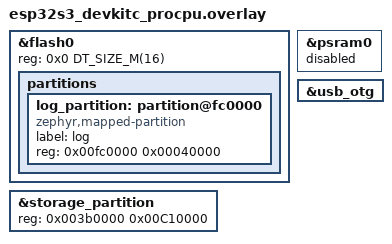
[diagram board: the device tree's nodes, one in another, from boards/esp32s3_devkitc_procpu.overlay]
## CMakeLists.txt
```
# SPDX-License-Identifier: Apache-2.0
#
# joy_bridge — Zephyr port of ESP32-BLE5-NSController-Emulator
# (Nintendo Switch Pro2 controller emulation over BLE).
#
# Migrated from the upstream ESP-IDF project. The layering is preserved:
#   - portable core: app/ (utils, state) / controller(HID) / codec(ns2)
#   - platform glue (Zephyr): ble/ (bt host), storage/ (settings)
#   - host input: usb_host/ (XInput class + host glue) + input/ (XInput->Pro2);
#                 the native UHC driver is the modules/uhc_dwc2_esp32 module

cmake_minimum_required(VERSION 3.20.0)

# Reusable in-tree Zephyr modules (must be on ZEPHYR_EXTRA_MODULES before
# find_package(Zephyr) so their Kconfig + sources are picked up):
#   - journal:        persistent flash-backed offline event log (CONFIG_JOURNAL)
#   - uhc_dwc2_esp32: native ESP32-S3 DWC2 USB host controller (CONFIG_UHC_DWC2)
list(APPEND ZEPHYR_EXTRA_MODULES
  ${CMAKE_CURRENT_SOURCE_DIR}/modules/journal
  ${CMAKE_CURRENT_SOURCE_DIR}/modules/uhc_dwc2_esp32
)

find_package(Zephyr REQUIRED HINTS $ENV{ZEPHYR_BASE})
project(joy_bridge C)

# Public headers (mirrors the upstream main/include tree).
target_include_directories(app PRIVATE include)

# Always-built portable core + platform glue. CONFIGURE_DEPENDS re-globs when
# files are added/removed so the build doesn't need a manual reconfigure.
file(GLOB_RECURSE app_sources CONFIGURE_DEPENDS
  src/main.c
  src/app/*.c
  src/controller/*.c
  src/codec/*.c
  src/ble/*.c
  src/storage/*.c
  src/input/*.c
  src/usb_host/*.c
)

target_sources(app PRIVATE ${app_sources})

# ---- USB host (input devices) -----------------------------------------------
# The native UHC host-controller driver now lives in the reusable module
# modules/uhc_dwc2_esp32 (added to ZEPHYR_EXTRA_MODULES above). The in-app class
# drivers (xinput_class.c / kbd_class.c) still use the experimental USB host
# stack's private class API (usbh_device.h / usbh_class.h) — no public header
# yet, same as the in-tree UVC host class — so they need that private include dir.
if(CONFIG_JOY_BRIDGE_USB_XINPUT OR CONFIG_JOY_BRIDGE_USB_KBD)
  target_include_directories(app PRIVATE ${ZEPHYR_BASE}/subsys/usb/host)
endif()
```

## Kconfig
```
# SPDX-License-Identifier: Apache-2.0
#
# Application Kconfig for joy_bridge. Mirrors the upstream main/Kconfig.projbuild
# options (symbol names kept identical to minimise churn in the ported sources)
# and adds Zephyr-specific knobs.

mainmenu "Joy Bridge (NS2 Controller Emulator)"

menu "NSController Configuration"

config MCU_DEBUG
	bool "Enable MCU debug logging"
	default n
	help
	  Enable detailed debug output for MCU operations (mirrors upstream
	  CONFIG_MCU_DEBUG). Prefer using the JOY_BRIDGE log level for runtime
	  filtering; this gates a handful of extra-verbose code paths.

config SAVE_PAIRING_INFO
	bool "Save pairing information"
	default y
	help
	  Persist pairing information (LTK / peer address) to non-volatile
	  storage for automatic reconnection on next boot.

config HID_REPORT_INTERVAL
	int "HID Report Interval (ms)"
	default 15
	range 5 100
	help
	  Interval between HID input report notifications. Lower values reduce
	  latency at the cost of CPU and BLE bandwidth. This is now only the
	  FALLBACK the report pacer uses when no link is up; with a connection
	  the send grid tracks the negotiated interval (clamped to 5-30 ms).

config JOY_BRIDGE_REPORT_BURST
	int "HID report fresh-input burst budget"
	default 3
	range 1 8
	help
	  How many fresh committed input reports may send back-to-back without
	  waiting for the send grid, per report_pacer.c. Sparse change-driven
	  input (e.g. keyboard) goes out immediately; dense streams degrade to
	  the interval cap once the burst is spent, protecting the BLE TX pool.

config JOY_BRIDGE_BLE_MIN_CONN_INTERVAL
	int "Requested minimum connection interval (units of 1.25 ms)"
	default 4
	help
	  Lower bound (in 1.25 ms units) the peripheral will accept when the NS2
	  console requests a connection-parameter update. 4 = 5 ms (sub-spec).
	  NOTE: the Zephyr host honours this only with BT_CONN_PARAM_ANY=y, and
	  the ESP32-S3 controller blob currently CANNOT enforce sub-7.5 ms — see
	  the 5 ms feasibility notes in src/ble/ble.c.

config JOY_BRIDGE_BLE_FAST_CONN_INTERVAL
	int "Post-pairing fast connection interval (units of 1.25 ms; 0 = off)"
	default 0
	help
	  After security level 4, request this connection interval from the NS2 to
	  cut input latency. Units of 1.25 ms; 4 = 5 ms / 200 Hz (prj.conf sets 4).
	  Verified on hardware: NS2 connects at 5 ms but power-saves to ~30 ms a few
	  seconds later; on_le_param_updated() re-requests this value whenever the
	  interval regresses above it, and NS2 then holds 5 ms. Requested only after
	  pairing so it cannot perturb the handshake; the negotiated result is logged
	  by on_le_param_updated(). 0 = never poke the link.

config JOY_BRIDGE_SLEEP_ON_NS2_OFF
	bool "Deep-sleep the ESP32 when the BLE link to the NS2 drops"
	select POWEROFF
	default n
	help
	  When the BLE link to the NS2 drops (the console sleeps / powers off, or
	  the link is otherwise lost), enter deep sleep instead of re-advertising.
	  Re-advertising the wake packet would immediately wake the console back up,
	  so this is the only way to actually power down with it (~10 uA). Wake by
	  pressing BOOT (GPIO0): the chip reboots, re-advertises, and the NS2
	  reconnects. Tap BOOT briefly — holding it through the wake-reset enters
	  serial-download mode, since GPIO0 is the boot strapping pin.

config JOY_BRIDGE_DIAG_HEXDUMP
	bool "DIAG: hexdump NS2 <-> controller ATT traffic"
	default n
	help
	  Capture the BLE application-layer protocol for reverse-engineering: log
	  every NS2<->controller ATT exchange as an INFO-level hexdump tagged
	  "[DIAG] ..." — command writes on 0x0016 (incl. the cmd-0x15 key
	  agreement), command responses on 0x001e, other inbound writes, the
	  constant reads, and CCC subscribe changes. grep a serial capture for
	  "[DIAG]" to lift out the raw bytes. Requires the JOY_BRIDGE log level to
	  be INF or higher. Leave OFF for normal use.

config JOY_BRIDGE_DIAG_HEXDUMP_HID
	bool "DIAG: also hexdump HID input reports (high rate)"
	depends on JOY_BRIDGE_DIAG_HEXDUMP
	default n
	help
	  Additionally hexdump every outbound HID input-report notification on
	  0x000e. These fire every HID_REPORT_INTERVAL ms (5-15), so this is very
	  verbose and can overrun the log backend; enable only for short captures.

config JOY_BRIDGE_DIAG_LATENCY
	bool "DIAG: measure input->notify latency and USB report rate"
	default n
	select UHC_DWC2_DIAG_LATENCY if UHC_DWC2
	help
	  Log, once per second, the rate of XInput reports consumed and the
	  average/max latency from an XInput report arriving to the resulting
	  HID notify being queued (in microseconds). For latency tuning; leave
	  OFF for normal use.

module = JOY_BRIDGE
module-str = joy_bridge
source "subsys/logging/Kconfig.template.log_config"

endmenu

source "Kconfig.zephyr"

# joy_bridge USB host (XInput) symbols. Sourced last so it can depend on the
# Zephyr UHC_DRIVER / USB_HOST_STACK symbols pulled in by Kconfig.zephyr.
# rsource: resolve relative to this file's dir (the app), not $srctree.
rsource "Kconfig.dwc2"
```

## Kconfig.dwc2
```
# SPDX-License-Identifier: Apache-2.0
#
# joy_bridge USB host input options.
#
# Sourced AFTER Kconfig.zephyr (see Kconfig) so the upstream USB_HOST_STACK
# symbol already exists and can be depended on here. The native DWC2 host-
# controller driver's Kconfig (CONFIG_UHC_DWC2) now lives in the reusable
# modules/uhc_dwc2_esp32 module.

config JOY_BRIDGE_USB_XINPUT
	bool "XInput USB host gamepad as the controller input source"
	depends on USB_HOST_STACK
	help
	  Read a wired XInput (Xbox-style) controller plugged into the ESP32-S3
	  USB-OTG port and map its gamepad reports onto the emulated Pro2 HID
	  report. Requires a working host controller (CONFIG_UHC_DWC2, provided by
	  the modules/uhc_dwc2_esp32 module).

config JOY_BRIDGE_USB_KBD
	bool "USB HID boot-protocol keyboard as a controller input source"
	depends on USB_HOST_STACK
	default n
	help
	  Read a wired USB HID boot-protocol keyboard (interface class 0x03,
	  subclass 0x01 boot, protocol 0x01 keyboard) plugged into the
	  ESP32-S3 USB-OTG port and merge its key presses with the XInput
	  input onto the emulated Pro2 HID report. Boot-protocol keyboards
	  only — NKRO/report-protocol-only keyboards are unsupported.
```

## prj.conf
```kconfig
# SPDX-License-Identifier: Apache-2.0
#
# joy_bridge application config. Target board: esp32s3_devkitc.

# ---- C library / heap -------------------------------------------------------
# The ported codec/controller use malloc()/free(); give libc a real arena.
CONFIG_COMMON_LIBC_MALLOC_ARENA_SIZE=32768
CONFIG_CPP=n

# ESP32-S3 external PSRAM: disabled for initial bring-up. The octal-mode config
# carried over from the Hello World overlay hangs early SoC init on boards
# without octal PSRAM. Not required by the app. Re-enable with the correct mode
# (quad vs octal) once the board PSRAM variant is confirmed.
# CONFIG_ESP_SPIRAM=y
# CONFIG_SPIRAM_MODE_OCT=y

# ---- Logging ----------------------------------------------------------------
CONFIG_LOG=y
CONFIG_JOY_BRIDGE_LOG_LEVEL_INF=y

# ---- Bluetooth host ---------------------------------------------------------
CONFIG_BT=y
CONFIG_BT_PERIPHERAL=y
CONFIG_BT_CENTRAL=n
CONFIG_BT_DEVICE_NAME="Pro Controller 2"

# Extended advertising (upstream uses ble_gap_ext_adv_* / legacy-PDU ext adv).
CONFIG_BT_EXT_ADV=y

# GATT server with our static service definition.
CONFIG_BT_GATT_DYNAMIC_DB=n

# No GATT robust caching — upstream NimBLE has none. Robust caching adds the
# Database-Hash / Client-Supported-Features attributes and can answer a client's
# first request with ATT "Database Out Of Sync" (0x12); both diverge from the
# table NS2 expects. (Default is y on this Zephyr.)
CONFIG_BT_GATT_CACHING=n

# *** Match the genuine Pro2 ATT table: drop the default GAP/GATT services ***
# ROOT CAUSE of "controller never appears" (proven by symmetric [DIAG] capture):
# NS2 connects (itvl=12, same as upstream) and exchanges MTU, then — unlike with
# upstream — issues NO subscribe and NO command write. It discovers the GATT
# table, finds the mandatory Zephyr GAP(0x1800)+GATT(0x1801) services that a real
# Pro2 lacks (these also shift HID 0x000e->0x0018 and the cmd channel
# 0x0016->0x001f), and silently declines. Upstream omits both default services
# (gatt.c: // ble_svc_gap_init(); // ble_svc_gatt_init();), so its table is the
# exact Pro2 layout starting at 0x0001.
#   BT_GAP_SVC=n               removes the GAP 0x1800 service (config-only).
#   BT_GATT_GAP_SVC_VALIDATE=n drops the spec "exactly one GAP service" check;
#                              otherwise bt_enable() returns -EINVAL with 0 GAP svcs.
#   BT_GATT_SERVICE_CHANGED=n  shrinks the GATT 0x1801 service to a 1-handle stub.
# (Fully removing 0x1801 + re-adding the Pro2 vendor descriptors for an EXACT
#  handle match would need a small Zephyr-host patch; this config-only step is the
#  first experiment — the [DIAG] write/subscribe handles on the next NS2 attempt
#  show whether removing GAP is sufficient or exact handles are still required.)
CONFIG_BT_GAP_SVC=n
CONFIG_BT_GATT_GAP_SVC_VALIDATE=n
CONFIG_BT_GATT_SERVICE_CHANGED=n

# Security / bonding. Upstream injects a pre-derived LTK rather than running a
# standard pairing exchange; keep SMP + settings-backed bonding available.
CONFIG_BT_SMP=y
CONFIG_BT_BONDABLE=y

# Match upstream's NS2 security model (src/device.c: sm_io_cap=NO_IO, sm_mitm=0,
# sm_sc=0 -> Just-Works, legacy-capable, UNauthenticated). Zephyr defaults the
# opposite (BT_SMP_ENFORCE_MITM=y and BT_SMP_SC_PAIR_ONLY=y, both `default y`),
# so the peripheral demands authenticated Secure-Connections-only pairing and
# would reject the console's Just-Works/legacy handshake -> no encryption -> the
# controller never registers on the Change Grip/Order screen. Disabling
# SC_PAIR_ONLY also compiles the legacy periph_ltk path in src/ble/ble_store.c
# so the injected NS2 LTK is served on the console's rand=0/ediv=0 enc request.
CONFIG_BT_SMP_ENFORCE_MITM=n
CONFIG_BT_SMP_SC_PAIR_ONLY=n
CONFIG_BT_SETTINGS=y
CONFIG_SETTINGS=y
CONFIG_FLASH=y
CONFIG_FLASH_MAP=y
CONFIG_NVS=y

# Single connection (one NS2 console at a time).
CONFIG_BT_MAX_CONN=1
CONFIG_BT_MAX_PAIRED=1

# BT RX work-queue stack. Incoming ATT (the GATT write callback ->
# cmd_process() -> cmd_0x15_handler()) runs here (CONFIG_BT_RECV_WORKQ_BT=y).
# The cmd-0x15 subcmd 0x02 path calls aes128_ecb() -> bt_encrypt_be(), which on
# this build resolves to the PSA/mbedTLS software AES (CONFIG_BT_HOST_CRYPTO=y,
# not the HCI LE-Encrypt path). That, plus the surrounding GATT/cmd processing,
# is deep enough to overflow the default 1200-byte stack and corrupt memory
# (observed: illegal-instruction fault in the scheduler ~1 ms after the
# subcmd-0x02 response, during the LTK exchange). Give it room.
CONFIG_BT_RX_STACK_SIZE=4096

# ATT MTU = 512 to match the genuine Pro2 (and upstream). The captured success
# trace shows NS2 negotiates MTU=512 then immediately reads 0x0003; our build
# negotiated only 247 and NS2 went silent right at that point. The server's RX
# ATT MTU is MIN(BT_L2CAP_RX_MTU, BT_L2CAP_TX_MTU), and BT_L2CAP_RX_MTU =
# BT_BUF_ACL_RX_SIZE - 4, so the RX buffer must be >= 516 to advertise MTU 512.
CONFIG_BT_L2CAP_TX_MTU=512
CONFIG_BT_BUF_ACL_TX_SIZE=251
CONFIG_BT_BUF_ACL_RX_SIZE=516

# *** 5 ms (sub-spec) connection interval enabler (HOST side) ***
# Removes the host's interval_min>=6 (7.5 ms) validation so the peripheral can
# accept the NS2 console's sub-spec params via the le_param_req callback.
# The CONTROLLER side (ESP32-S3 blob) is a separate, currently-unsolved gate:
# see the feasibility notes at the top of src/ble/ble.c.
CONFIG_BT_CONN_PARAM_ANY=y

# Post-pairing/reconnect fast connection interval (units of 1.25 ms).
# 4 = 5 ms / 200 Hz, matching the interval NS2 uses natively in its fast mode.
# On wake/reconnect NS2 frequently settles on its ~30 ms power-save interval and
# nothing pulls it back down, so input lags. fast_interval_work_fn() requests
# this value once security reaches L4 (fresh-pair OR bonded reconnect), retrying
# a few times. The controller floor is 3.75 ms so a 5 ms grant is accepted.
CONFIG_JOY_BRIDGE_BLE_FAST_CONN_INTERVAL=4

# HID input-report cadence (ms) — left at the default 15 ms. NOTE: a 5 ms cadence
# (to match the fast link) was tried and REGRESSED input on hardware: the NS2
# power-saves the link to ~30 ms periodically, and sending every 5 ms then floods
# the small BLE TX buffer pool (the "12 != 10" ACL/tx-context margin), so HID
# notifies stall/-ENOMEM and reports stop reaching the console. A proper low-
# latency cadence must track the *negotiated* connection interval rather than use
# a fixed value — see the report loop in src/controller/hid_controller.c.

# Use a fixed public identity address (upstream sets a Nintendo-prefixed MAC).
CONFIG_BT_PRIVACY=n

# Deep-sleep the ESP32 when the BLE link to the NS2 drops, instead of
# re-advertising (which would wake the console back up). Wake = BOOT/GPIO0
# press -> reboot -> re-advertise. Selects CONFIG_POWEROFF (sys_poweroff()).
CONFIG_JOY_BRIDGE_SLEEP_ON_NS2_OFF=y

# ---- Console / logging UART -------------------------------------------------
# Serial console for boot logs and the [DIAG] BLE captures. Host input is not a
# UART byte stream — it comes from XInput over USB host (see below).
CONFIG_SERIAL=y
CONFIG_UART_INTERRUPT_DRIVEN=y

# ---- USB host (XInput controller input) ------------------------------------
# Bring the on-chip ESP32-S3 USB-OTG core up in HOST mode (Full-Speed) and run
# the experimental Zephyr USB host stack, so a wired XInput (Xbox) controller
# plugged into the USB-OTG port drives the emulated Pro2.
#
# Upstream Zephyr has NO DWC2 host (UHC) driver for the S3 OTG core, so
# CONFIG_UHC_DWC2 selects the in-app uhc_dwc2_esp32 driver (and makes
# hal_espressif compile its USB wrapper HAL). USB host + UHC are EXPERIMENTAL
# (CONFIG_EXPERIMENTAL is auto-selected by USB_HOST_STACK / UHC_DRIVER).
CONFIG_USB_HOST_STACK=y
CONFIG_UHC_DRIVER=y
CONFIG_UHC_DWC2=y
CONFIG_JOY_BRIDGE_USB_XINPUT=y
# USB HID boot-protocol keyboard as a second input source (merged with the pad:
# buttons OR, sticks last-writer-wins). Boot-protocol only — see AGENTS.md.
CONFIG_JOY_BRIDGE_USB_KBD=y

# ---- Persistent event journal (offline diagnostics) -------------------------
# Record curated low-rate events (boot+reset cause, BLE connect/disconnect+reason,
# security level, conn-interval changes, deep-sleep entry, USB bind) to a
# dedicated flash partition (log_partition, top 256 KB), replayed to the console
# on the next boot. Lets the device's behaviour while running on battery with no
# serial console be reviewed after the fact. Backed by FCB on its own partition —
# does NOT touch the NVS partition holding the NS2 bond. Provided by the reusable
# `journal` Zephyr module (modules/journal/); main.c calls journal_init() with
# log_partition's area id and ble_hid_ready as the flash-write gate.
CONFIG_JOURNAL=y
```

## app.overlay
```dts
/* 1. Expand total physical flash size to 16 MB */
&flash0 {
    reg = <0x0 DT_SIZE_M(16)>;
};

/* 2. Stretch the storage partition */
&storage_partition {
    reg = <0x003b0000 0x00C50000>;
};

/* 3. Enable the internal 8 MB PSRAM */
&psram0 {
    status = "okay";
    size = <DT_SIZE_M(8)>;
};

/* 4. Bring up USB-OTG in HOST mode for the XInput controller bridge.
 *
 * Reuse the existing "espressif,esp32-usb-otg" node (its binding includes
 * snps,dwc2.yaml, providing reg/interrupts/clocks). USB *device* (UDC) mode is
 * left disabled in prj.conf, so nothing else binds this compatible; the in-app
 * host driver binds it via DT_DRV_COMPAT espressif_esp32_usb_otg.
 */
&usb_otg {
    status = "okay";
};
```

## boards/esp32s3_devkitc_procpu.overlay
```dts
/*
 * Board-specific devicetree overlay for esp32s3_devkitc.
 *
 * Zephyr auto-applies boards/<board>.overlay when this board is the build
 * target (BOARD=esp32s3_devkitc/esp32s3/procpu), so this file needs no CMake
 * wiring. It holds the DevKitC-1 flash/PSRAM layout and the USB-OTG host-mode
 * bring-up for the XInput controller bridge.
 */

/* 1. Expand total physical flash size to 16 MB */
&flash0 {
    reg = <0x0 DT_SIZE_M(16)>;
};

/* 2. Stretch the storage partition.
 * Ends at 0xfc0000 (not 0x1000000): the top 256 KB is reserved for the
 * persistent-trace partition below. The start stays at 0x3b0000, and NVS fills
 * from the start, so the existing NS2 bond (in the low sectors) is unaffected by
 * trimming the unused tail. */
&storage_partition {
    reg = <0x003b0000 0x00C10000>;
};

/* 2a. Persistent event journal ring (CONFIG_JOURNAL).
 * Top 256 KB of flash, its own partition so the journal never shares the NVS
 * partition that holds the load-bearing bond. Bound by FCB in the reusable
 * `journal` module (modules/journal/), which main() points here by passing
 * PARTITION_ID(log_partition) to journal_init(). esptool-pullable:
 *   esptool read-flash 0xfc0000 0x40000 journal.bin (then `strings journal.bin`). */
&flash0 {
    partitions {
        log_partition: partition@fc0000 {
            /* Same compatible as every sibling in this AMP layout — the parent
             * `partitions` node is not a `fixed-partitions` node, so PARTITION_ID()
             * resolves via the mapped-partition path (as storage_partition does). */
            compatible = "zephyr,mapped-partition";
            label = "log";
            reg = <0x00fc0000 0x00040000>;
        };
    };
};

/* 3. PSRAM: left DISABLED, to match prj.conf (CONFIG_ESP_SPIRAM is off).
 * The octal-mode SPIRAM config carried over from the Hello-World overlay hung
 * early SoC init on this board, and the app does not need PSRAM. Keeping the node
 * disabled (rather than "okay" with an 8 MB size that nothing initialises) avoids
 * a half-enabled trap: re-enabling means flipping BOTH this status — with the
 * correct size — AND the Kconfig (CONFIG_ESP_SPIRAM + the right SPIRAM_MODE_xxx)
 * together. See AGENTS.md "Current state & known gaps". */
&psram0 {
    status = "disabled";
};

/* 4. Bring up USB-OTG in HOST mode for the XInput controller bridge.
 *
 * Reuse the existing "espressif,esp32-usb-otg" node (its binding includes
 * snps,dwc2.yaml, providing reg/interrupts/clocks). USB *device* (UDC) mode is
 * left disabled in prj.conf, so nothing else binds this compatible; the in-app
 * host driver binds it via DT_DRV_COMPAT espressif_esp32_usb_otg.
 */
&usb_otg {
    status = "okay";
};
```

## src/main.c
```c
/*
 * joy_bridge — application entry point.
 * Zephyr port of the upstream ESP-IDF app_main() init sequence.
 */

#include <zephyr/kernel.h>

#include "device.h"
#include "controller/hid_controller.h"
#include "storage.h"
#include "usb_host.h"
#include "ble/ble_iface.h"            /* ble_hid_ready() — journal flash-write gate */

#include <zephyr/storage/flash_map.h> /* PARTITION_ID(log_partition) */
#include <zephyr/logging/log.h>
LOG_MODULE_REGISTER(jb_app, CONFIG_JOY_BRIDGE_LOG_LEVEL);
#include "app_log.h"
#include <journal/journal.h>

int main(void) {
    /* First: replay any persisted offline journal to the console and mark this
     * boot (with the reset cause). Done before other init so the dump leads and
     * does not interleave with normal log output. Persists to log_partition;
     * ble_hid_ready gates flash writes to the settled-link window (never during
     * boot/pairing). No-op unless CONFIG_JOURNAL. */
    journal_init(PARTITION_ID(log_partition), ble_hid_ready);

    ESP_LOGI(LOG_APP, "Nintendo Switch Controller Emulator (joy_bridge)");
    ESP_LOGI(LOG_APP, "Starting initialization...");

    /* Persistent storage (settings) for controller config + pairing info. */
    if (storage_init() != 0) {
        ESP_LOGE(LOG_APP, "Storage init failed; continuing without persistence");
    }

    /* Controller type + firmware/pairing data from storage. */
    controller_type_init();
    if (controller_init() == 0) {
        ESP_LOGI(LOG_APP, "Controller firmware loaded (paired)");
    } else {
        ESP_LOGW(LOG_APP, "No pairing info; will pair on first connection");
    }

    /* HID report engine (double buffer + report thread, idle until subscribed). */
    if (g_hid_controller.ops->init(&g_hid_controller, g_controller_firmware.type) == 0) {
        ESP_LOGI(LOG_APP, "Controller initialized");
    } else {
        ESP_LOGE(LOG_APP, "Failed to initialize controller");
    }

    /* BLE stack: GATT service, identity, advertising. */
    if (ble_stack_init() != 0) {
        ESP_LOGE(LOG_APP, "BLE stack init failed");
    } else {
        ESP_LOGI(LOG_APP, "BLE stack initialized");
    }

#if defined(CONFIG_JOY_BRIDGE_USB_XINPUT) || defined(CONFIG_JOY_BRIDGE_USB_KBD)
    /* USB host (XInput pad / HID keyboard input). Started after BLE — the
     * load-bearing path comes up first, and a USB failure must never block it. */
    if (usb_host_start() == 0) {
        ESP_LOGI(LOG_APP, "USB host started");
    } else {
        ESP_LOGE(LOG_APP, "USB host start failed; continuing without host input");
    }
#endif

    /* Zephyr keeps the kernel + worker threads running after main returns. */
    return 0;
}
```

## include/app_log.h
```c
#ifndef _APP_LOG_H_
#define _APP_LOG_H_

/*
 * ESP-IDF -> Zephyr logging shim.
 *
 * The ported sources use ESP_LOGx(TAG, fmt, ...). Zephyr selects the log module
 * per translation unit, so the TAG argument is unused here (it is still defined
 * as a string literal elsewhere, e.g. LOG_APP/LOG_HID, and simply discarded by
 * these macros).
 *
 * LOG modules are grouped by subsystem (jb_app, jb_ble, jb_codec, jb_ctrl,
 * jb_storage, jb_usb). Before including this header, the subsystem's primary .c
 * registers the module and the other .c files in that subsystem declare it:
 *
 *     #include <zephyr/logging/log.h>
 *     LOG_MODULE_REGISTER(jb_<subsys>, CONFIG_JOY_BRIDGE_LOG_LEVEL);  // once per subsystem
 *     // ...or, in the subsystem's other files:
 *     LOG_MODULE_DECLARE(jb_<subsys>, CONFIG_JOY_BRIDGE_LOG_LEVEL);
 *     #include "app_log.h"
 */

#include <zephyr/logging/log.h>

#define ESP_LOGE(tag, ...) LOG_ERR(__VA_ARGS__)
#define ESP_LOGW(tag, ...) LOG_WRN(__VA_ARGS__)
#define ESP_LOGI(tag, ...) LOG_INF(__VA_ARGS__)
#define ESP_LOGD(tag, ...) LOG_DBG(__VA_ARGS__)

#endif /* _APP_LOG_H_ */
```

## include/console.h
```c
#ifndef _CONSOLE_H_
#define _CONSOLE_H_

#include <stdint.h>

#define NS2_BD_ADDR_LEN 6

/*
 * Portable BLE address holder. Decoupled from any host-stack address type so
 * the codec/controller layers do not pull in the Zephyr bluetooth headers.
 * The ble/ layer translates to/from bt_addr_le_t.
 *
 * val[] is stored little-endian (LSB first), matching the upstream NimBLE
 * ble_addr_t convention and Zephyr's bt_addr_le_t.
 */
typedef struct {
    uint8_t type;                   /* 0 = public */
    uint8_t val[NS2_BD_ADDR_LEN];
} ns2_addr_t;

typedef struct {
    ns2_addr_t ble_addr;
    uint16_t   conn_handle;         /* legacy field; see ble layer for live conn */
    uint16_t   mtu;
} console_ns2_t;

extern console_ns2_t g_console_ns2;

#endif /* _CONSOLE_H_ */
```

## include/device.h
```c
#ifndef _DEVICE_H_
#define _DEVICE_H_

/*
 * Central application header for the portable core. Aggregates the cross-layer
 * declarations the upstream sources expect from "device.h", but free of any
 * host-stack (NimBLE/Zephyr-bt) types — those live behind ble/ble_iface.h.
 */

#include <stdint.h>
#include <stdbool.h>

#include "console.h"
#include "controller/controller.h"
#include "ble/ble_iface.h"

/* Log "tags" — kept as string literals for call-site parity with the upstream
 * ESP_LOGx(TAG, ...) calls. The app_log.h shim discards the tag argument; the
 * active Zephyr log module is chosen per-file via LOG_MODULE_REGISTER(). */
#define LOG_APP        "app"
#define LOG_HID        "hid"
#define LOG_BLE_GATT   "ble_gatt"
#define LOG_BLE_GAP    "ble_gap"
#define LOG_BLE_NVS    "ble_nvs"

#endif /* _DEVICE_H_ */
```

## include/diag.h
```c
/*
 * DIAG — config-gated hexdump capture of the NS2 <-> controller ATT traffic.
 *
 * Enable with CONFIG_JOY_BRIDGE_DIAG_HEXDUMP=y (and, for the high-rate HID
 * input reports, CONFIG_JOY_BRIDGE_DIAG_HEXDUMP_HID=y). Every captured PDU is
 * emitted at INFO level tagged "[DIAG] ...", so a serial capture can be grepped
 * for "[DIAG]" and the raw bytes lifted out for offline analysis (e.g. feed to
 * Wireshark via text2pcap). Disabled builds compile these to nothing.
 *
 * Include AFTER LOG_MODULE_REGISTER()/app_log.h in the .c file so the LOG_*
 * macros bind to that translation unit's log module.
 *
 * The tag passed to LOG_DIAG_DUMP must be a string literal: it is concatenated
 * with "[DIAG] " at compile time, which also keeps the hexdump label pointer in
 * static storage (deferred logging stores the label by pointer, not by copy).
 */
#ifndef _DIAG_H_
#define _DIAG_H_

#include <zephyr/logging/log.h>

#if defined(CONFIG_JOY_BRIDGE_DIAG_HEXDUMP)
#define LOG_DIAG(...)              LOG_INF(__VA_ARGS__)
#define LOG_DIAG_DUMP(tag, d, l)   LOG_HEXDUMP_INF((d), (l), "[DIAG] " tag)
#else
#define LOG_DIAG(...)              ((void)0)
#define LOG_DIAG_DUMP(tag, d, l)   ((void)0)
#endif

#if defined(CONFIG_JOY_BRIDGE_DIAG_HEXDUMP_HID)
#define LOG_DIAG_DUMP_HID(tag, d, l)  LOG_HEXDUMP_INF((d), (l), "[DIAG] " tag)
#else
#define LOG_DIAG_DUMP_HID(tag, d, l)  ((void)0)
#endif

#endif /* _DIAG_H_ */
```

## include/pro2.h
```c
#ifndef _PRO2_H_
#define _PRO2_H_

/* Pro2-specific device init and pairing persistence. */

int pro2_device_init(void);
int pro2_pairing_info_save(void);
int pro2_pairing_info_erase(void);

#endif /* _PRO2_H_ */
```

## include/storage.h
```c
#ifndef _STORAGE_H_
#define _STORAGE_H_

/*
 * Tiny key/value persistence abstraction, replacing the upstream ESP-IDF NVS
 * usage. Backed by the Zephyr settings subsystem (see src/storage/storage.c).
 *
 * Keys are namespaced (namespace + key) the same way the original code grouped
 * values into NVS namespaces (CONFIG / PAIRING_PRO2 / ...).
 */

#include <stdint.h>
#include <stddef.h>

/* Namespaces (mirror upstream NVS namespace names). */
#define STORAGE_NS_CONFIG        "config"
#define STORAGE_NS_PAIRING_PRO2  "pair_pro2"
#define STORAGE_NS_PAIRING_JC    "pair_jc"

/* Keys (mirror upstream NVS keys). */
#define STORAGE_KEY_CONTROLLER_TYPE  "ctrl_type"
#define STORAGE_KEY_CTRL_ADDR        "ctrl_mac"
#define STORAGE_KEY_HOST_ADDR        "host_mac"
#define STORAGE_KEY_LTK              "ble_ltk"

#ifdef __cplusplus
extern "C" {
#endif

/* Initialise the storage backend. Returns 0 on success. */
int storage_init(void);

/* Read a blob. On entry *len is the buffer capacity; on success it holds the
 * bytes read. Returns 0 on success, -ENOENT if absent, other negative errno
 * on error. */
int storage_get_blob(const char *ns, const char *key, void *out, size_t *len);

/* Write a blob. Returns 0 on success. */
int storage_set_blob(const char *ns, const char *key, const void *in, size_t len);

/* Read / write a single byte. */
int storage_get_u8(const char *ns, const char *key, uint8_t *out);
int storage_set_u8(const char *ns, const char *key, uint8_t val);

/* Erase every key under a namespace. Returns 0 on success. */
int storage_erase_namespace(const char *ns);

#ifdef __cplusplus
}
#endif

#endif /* _STORAGE_H_ */
```

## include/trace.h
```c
#ifndef _TRACE_H_
#define _TRACE_H_

/*
 * Persistent event trace — a curated, low-rate log of significant runtime
 * events written to a dedicated flash partition (log_partition) so the device's
 * behaviour while running *offline* (on battery, no serial console attached) can
 * be reviewed later.
 *
 * On boot the previously stored trace is dumped to the console; new events are
 * appended durably (each append commits to flash, so an abrupt power loss — e.g.
 * a flat battery — loses at most the line in flight). Backed by Zephyr's Flash
 * Circular Buffer over its OWN partition; it never touches the settings/NVS
 * partition that holds the load-bearing NS2 bond. See src/app/trace.c.
 *
 * Gated by CONFIG_JOY_BRIDGE_PERSIST_LOG; compiles to nothing when disabled.
 */

#include <zephyr/toolchain.h>

#ifdef __cplusplus
extern "C" {
#endif

#ifdef CONFIG_JOY_BRIDGE_PERSIST_LOG

/* Mount the flash ring, replay any stored events to the console, and append a
 * boot marker (with the reset cause). Call once, early in main(). */
void jb_trace_init(void);

/* Record one curated event. The line is enqueued to a small RAM ring and
 * written to flash later by a low-priority worker (only once the BLE link is
 * settled) — NEVER inline, because writing the on-chip flash stalls the XIP
 * cache and disrupts the BLE controller and the boot/pairing path. The caller
 * keeps its own LOG_* line for the live console. Low-rate use only; safe from
 * any thread context (BLE/USB callbacks included). */
__printf_like(1, 2) void jb_trace(const char *fmt, ...);

/* Synchronously flush all pending events to flash. Call ONLY when the BLE link
 * is down (e.g. just before deep sleep), where a flash write is safe. */
void jb_trace_flush(void);

#else /* !CONFIG_JOY_BRIDGE_PERSIST_LOG */

static inline void jb_trace_init(void) {}
static inline __printf_like(1, 2) void jb_trace(const char *fmt, ...) { ARG_UNUSED(fmt); }
static inline void jb_trace_flush(void) {}

#endif /* CONFIG_JOY_BRIDGE_PERSIST_LOG */

#ifdef __cplusplus
}
#endif

#endif /* _TRACE_H_ */
```

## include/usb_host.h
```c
#ifndef JOY_BRIDGE_USB_HOST_H
#define JOY_BRIDGE_USB_HOST_H

#ifdef __cplusplus
extern "C" {
#endif

/*
 * Initialise and enable the USB host stack, then begin polling for an input
 * device on the ESP32-S3 USB-OTG port — a wired XInput controller and/or a
 * USB HID boot-protocol keyboard (whichever binds; no hub support, so never
 * both at once). Reports from a connected device are merged and mapped onto
 * the emulated Pro2 HID report.
 *
 * Returns 0 on success, negative errno on failure. A failure here must not
 * block BLE bring-up — the caller logs and continues. Only meaningful when
 * CONFIG_JOY_BRIDGE_USB_XINPUT or CONFIG_JOY_BRIDGE_USB_KBD is enabled.
 */
int usb_host_start(void);

#ifdef __cplusplus
}
#endif

#endif /* JOY_BRIDGE_USB_HOST_H */
```

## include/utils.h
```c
#ifndef _UTILS_H_
#define _UTILS_H_

#include <stdint.h>
#include <stddef.h>

/* Reverse the order of bytes in an array. */
void reverse_bytes(const uint8_t *in, uint8_t *out, size_t len);

/* Encrypt one 16-byte block using AES-128 in ECB mode. Returns 0 on success. */
int aes128_ecb(const uint8_t *key, const uint8_t *in, uint8_t *out);

/* Print a 16-byte key (hex). */
void log_print_ltk_hex(const char *data_name, const uint8_t *data);

/* Print a 6-byte BLE address (stored little-endian). */
void log_print_addr(const void *addr);

#endif /* _UTILS_H_ */
```
